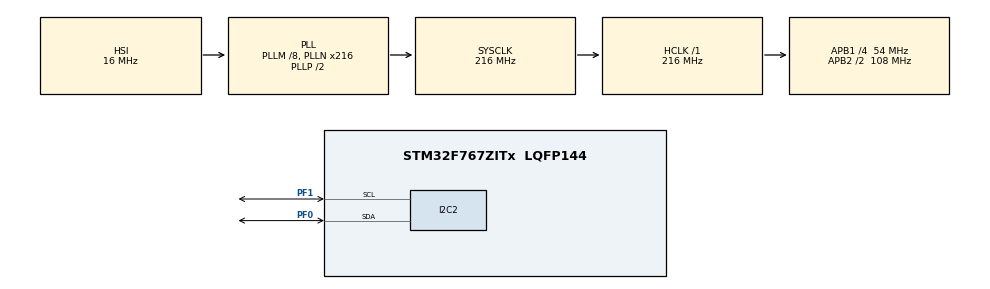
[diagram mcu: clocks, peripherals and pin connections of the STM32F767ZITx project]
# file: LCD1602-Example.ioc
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CORTEX_M7.default_mode_Activation=1
I2C2.Timing=0x20404768
Mcu.Family=STM32F7
Mcu.Name=STM32F767ZITx
Mcu.Package=LQFP144
NVIC.PriorityGroup=NVIC_PRIORITYGROUP_4
PF0.Mode=I2C
PF0.Signal=I2C2_SDA
PF1.Mode=I2C
PF1.Signal=I2C2_SCL
ProjectManager.HeapSize=0x200
ProjectManager.StackSize=0x400
ProjectManager.TargetToolchain=STM32CubeIDE
RCC.AHBFreq_Value=216000000
RCC.APB1CLKDivider=RCC_HCLK_DIV4
RCC.APB1Freq_Value=54000000
RCC.APB1TimFreq_Value=108000000
RCC.APB2CLKDivider=RCC_HCLK_DIV2
RCC.APB2Freq_Value=108000000
RCC.APB2TimFreq_Value=216000000
RCC.CortexFreq_Value=216000000
RCC.HCLKFreq_Value=216000000
RCC.HSE_VALUE=25000000
RCC.HSI_VALUE=16000000
RCC.LSE_VALUE=32768
RCC.PLLM=8
RCC.PLLN=216
RCC.SYSCLKFreq_VALUE=216000000
RCC.SYSCLKSource=RCC_SYSCLKSOURCE_PLLCLK
RCC.USBFreq_Value=216000000
RCC.VCOOutputFreq_Value=432000000
board=custom

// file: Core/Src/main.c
/* USER CODE BEGIN Header */
/**
  ******************************************************************************
  * @file           : main.c
  * @brief          : Main program body
  ******************************************************************************
  * @attention
  *
  * Copyright (c) 2025 STMicroelectronics.
  * All rights reserved.
  *
  * This software is licensed under terms that can be found in the LICENSE file
  * in the root directory of this software component.
  * If no LICENSE file comes with this software, it is provided AS-IS.
  *
  ******************************************************************************
  */
/* USER CODE END Header */
#include "main.h"

/* USER CODE BEGIN Includes */
#include "i2c-lcd.h"
/* USER CODE END Includes */

/* USER CODE BEGIN PD */
#define LCD_ADDRESS 0x27
/* USER CODE END PD */

I2C_HandleTypeDef hi2c2;

/* USER CODE BEGIN PV */
Lcd_HandleTypeDef* lcd;
int integer = 42;
float my_float = 42.42;

char block[] = {
		CUSTOM_CHAR_MEM_01,
		0x1F,
		0x00,
		0x1F,
		0x00,
		0x1F,
		0x00,
		0x1F
};
/* USER CODE END PV */

void SystemClock_Config(void);
static void MPU_Config(void);
static void MX_GPIO_Init(void);
static void MX_I2C2_Init(void);

int main(void)
{

  /* MPU Configuration--------------------------------------------------------*/
  MPU_Config();

  /* MCU Configuration--------------------------------------------------------*/

  /* Reset of all peripherals, Initializes the Flash interface and the Systick. */
  HAL_Init();

  /* Configure the system clock */
  SystemClock_Config();

  /* Initialize all configured peripherals */
  MX_GPIO_Init();
  MX_I2C2_Init();
  /* USER CODE BEGIN 2 */
  lcd = lcd_open(&hi2c2, LCD_ADDRESS, NO_RTOS);
  lcd_init(lcd);
  lcd_write(lcd, (void*)block, CREATE_CHAR);
  /* USER CODE END 2 */

  /* Infinite loop */
  /* USER CODE BEGIN WHILE */
  while (1) {
		lcd_write(lcd, (void*)"Hello, World", WRITE_STRING);
		HAL_Delay(1000);

		lcd_ioctrl(lcd, CLEAR_DISPLAY);
		lcd_write(lcd, (void*)"Cleared", WRITE_STRING);

		HAL_Delay(1000);

		lcd_ioctrl(lcd, CLEAR_DISPLAY);
		lcd_ioctrl(lcd, DDRAM_SET|ROW_02|COL_01);
		lcd_write(lcd, (void*)"Cur Move", WRITE_STRING);
		lcd_ioctrl(lcd, DDRAM_SET|ROW_01|COL_07);
		lcd_write(lcd, (void*)&integer, WRITE_INT);

		HAL_Delay(1000);

		lcd_ioctrl(lcd, CLEAR_DISPLAY);
		lcd_ioctrl(lcd, RET_HOME);
		lcd_write(lcd, (void*)&my_float, WRITE_FLOAT);

		HAL_Delay(1000);

		lcd_ioctrl(lcd, CLEAR_DISPLAY);
		lcd_ioctrl(lcd, RET_HOME);
		lcd_write(lcd, (void*)&CUSTOM_CHAR_01, WRITE_CUSTOM);

		HAL_Delay(1000);

		lcd_close(lcd);
		lcd = lcd_open(&hi2c2, LCD_ADDRESS, NO_RTOS);
		lcd_init(lcd);
    /* USER CODE END WHILE */

  }
}

void SystemClock_Config(void)
{
  RCC_OscInitTypeDef RCC_OscInitStruct = {0};
  RCC_ClkInitTypeDef RCC_ClkInitStruct = {0};

  /** Configure the main internal regulator output voltage
  */
  __HAL_RCC_PWR_CLK_ENABLE();
  __HAL_PWR_VOLTAGESCALING_CONFIG(PWR_REGULATOR_VOLTAGE_SCALE1);

  /** Initializes the RCC Oscillators according to the specified parameters
  * in the RCC_OscInitTypeDef structure.
  */
  RCC_OscInitStruct.OscillatorType = RCC_OSCILLATORTYPE_HSI;
  RCC_OscInitStruct.HSIState = RCC_HSI_ON;
  RCC_OscInitStruct.HSICalibrationValue = RCC_HSICALIBRATION_DEFAULT;
  RCC_OscInitStruct.PLL.PLLState = RCC_PLL_ON;
  RCC_OscInitStruct.PLL.PLLSource = RCC_PLLSOURCE_HSI;
  RCC_OscInitStruct.PLL.PLLM = 8;
  RCC_OscInitStruct.PLL.PLLN = 216;
  RCC_OscInitStruct.PLL.PLLP = RCC_PLLP_DIV2;
  RCC_OscInitStruct.PLL.PLLQ = 2;
  RCC_OscInitStruct.PLL.PLLR = 2;
  if (HAL_RCC_OscConfig(&RCC_OscInitStruct) != HAL_OK)
  {
    Error_Handler();
  }

  /** Activate the Over-Drive mode
  */
  if (HAL_PWREx_EnableOverDrive() != HAL_OK)
  {
    Error_Handler();
  }

  /** Initializes the CPU, AHB and APB buses clocks
  */
  RCC_ClkInitStruct.ClockType = RCC_CLOCKTYPE_HCLK|RCC_CLOCKTYPE_SYSCLK
                              |RCC_CLOCKTYPE_PCLK1|RCC_CLOCKTYPE_PCLK2;
  RCC_ClkInitStruct.SYSCLKSource = RCC_SYSCLKSOURCE_PLLCLK;
  RCC_ClkInitStruct.AHBCLKDivider = RCC_SYSCLK_DIV1;
  RCC_ClkInitStruct.APB1CLKDivider = RCC_HCLK_DIV4;
  RCC_ClkInitStruct.APB2CLKDivider = RCC_HCLK_DIV2;

  if (HAL_RCC_ClockConfig(&RCC_ClkInitStruct, FLASH_LATENCY_7) != HAL_OK)
  {
    Error_Handler();
  }
}

static void MX_I2C2_Init(void)
{

  hi2c2.Instance = I2C2;
  hi2c2.Init.Timing = 0x20404768;
  hi2c2.Init.OwnAddress1 = 0;
  hi2c2.Init.AddressingMode = I2C_ADDRESSINGMODE_7BIT;
  hi2c2.Init.DualAddressMode = I2C_DUALADDRESS_DISABLE;
  hi2c2.Init.OwnAddress2 = 0;
  hi2c2.Init.OwnAddress2Masks = I2C_OA2_NOMASK;
  hi2c2.Init.GeneralCallMode = I2C_GENERALCALL_DISABLE;
  hi2c2.Init.NoStretchMode = I2C_NOSTRETCH_DISABLE;
  if (HAL_I2C_Init(&hi2c2) != HAL_OK)
  {
    Error_Handler();
  }

  /** Configure Analogue filter
  */
  if (HAL_I2CEx_ConfigAnalogFilter(&hi2c2, I2C_ANALOGFILTER_ENABLE) != HAL_OK)
  {
    Error_Handler();
  }

  /** Configure Digital filter
  */
  if (HAL_I2CEx_ConfigDigitalFilter(&hi2c2, 0) != HAL_OK)
  {
    Error_Handler();
  }

}

static void MX_GPIO_Init(void)
{

  /* GPIO Ports Clock Enable */
  __HAL_RCC_GPIOF_CLK_ENABLE();

}

 /* MPU Configuration */

void MPU_Config(void)
{
  MPU_Region_InitTypeDef MPU_InitStruct = {0};

  /* Disables the MPU */
  HAL_MPU_Disable();

  /** Initializes and configures the Region and the memory to be protected
  */
  MPU_InitStruct.Enable = MPU_REGION_ENABLE;
  MPU_InitStruct.Number = MPU_REGION_NUMBER0;
  MPU_InitStruct.BaseAddress = 0x0;
  MPU_InitStruct.Size = MPU_REGION_SIZE_4GB;
  MPU_InitStruct.SubRegionDisable = 0x87;
  MPU_InitStruct.TypeExtField = MPU_TEX_LEVEL0;
  MPU_InitStruct.AccessPermission = MPU_REGION_NO_ACCESS;
  MPU_InitStruct.DisableExec = MPU_INSTRUCTION_ACCESS_DISABLE;
  MPU_InitStruct.IsShareable = MPU_ACCESS_SHAREABLE;
  MPU_InitStruct.IsCacheable = MPU_ACCESS_NOT_CACHEABLE;
  MPU_InitStruct.IsBufferable = MPU_ACCESS_NOT_BUFFERABLE;

  HAL_MPU_ConfigRegion(&MPU_InitStruct);
  /* Enables the MPU */
  HAL_MPU_Enable(MPU_PRIVILEGED_DEFAULT);

}

void Error_Handler(void)
{
  __disable_irq();
  while (1)
  {
  }
}
